AUTOSAR XML (schema 00050)
standard types defined: Float
package /ARRoot
  trigger-interface:
    trigger PowerWindowLeftTrigger
    trigger PowerWindowRightTrigger
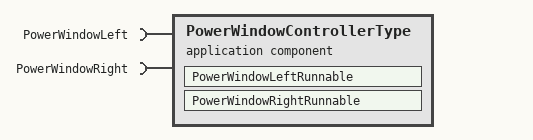
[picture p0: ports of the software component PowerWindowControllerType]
  application sw component type PowerWindowControllerType
    require port PowerWindowLeft
    require port PowerWindowRight
    behavior PowerWindowControllerIB
      runnable PowerWindowLeftRunnable: synchronous-server-call-point=PowerWindowLeft.
      runnable PowerWindowRightRunnable: synchronous-server-call-point=PowerWindowRight.
  swc implementation PowerWindowImpFile: programming-language=C, behavior=PowerWindowControllerIB
  client server interface PowerWindowLeftCSIF: client-server-operation=arguments=argument-data-prototype={type=Float, direction=OUT}
  client server interface PowerWindowRightCSIF: client-server-operation=arguments=argument-data-prototype={type=Float, direction=OUT}
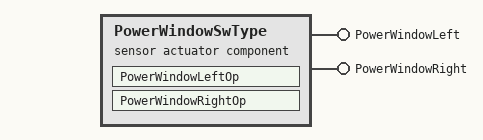
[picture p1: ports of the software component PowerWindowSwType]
  sensor actuator sw component type PowerWindowSwType
    provide port PowerWindowLeft
    provide port PowerWindowRight
    behavior PowerWindowIB
      runnable PowerWindowLeftOp: external-triggering-point=PowerWindowLeft.PowerWindowLeftTrigger
      runnable PowerWindowRightOp: external-triggering-point=PowerWindowRight.PowerWindowRightTrigger
